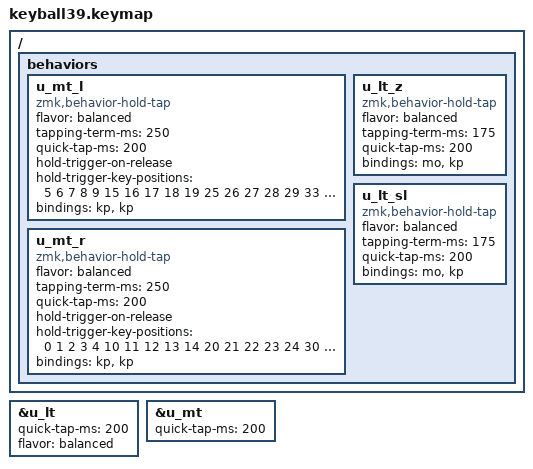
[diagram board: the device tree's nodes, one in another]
// Miryoku keymap for Keyball39
// https://github.com/manna-harbour/miryoku_zmk

#include "keyball39_custom_config.h"
#include "mapping/39/keyball39.h"
#include "../miryoku/miryoku/miryoku.dtsi"

// Charybdis-style hold-tap tuning (see keyball39_custom_config.h for the base
// override that wires these in).
//
// Keyball39 hand split (matrix-transform positions):
//   left  = 0-4 10-14 20-24 30-35   right = 5-9 15-19 25-29 36-38
/ {
    behaviors {
        // Home-row mods: Permissive Hold (balanced) + Chordal Hold (positional).
        // A mod holds when the OTHER hand OR a same-hand thumb (33-38) follows,
        // so alpha rolls (as/en) stay taps but mod+thumb chords (Ctrl+Space,
        // Ctrl+Bspc) fire. hold-trigger-on-release lets same-hand mod combos
        // still work. tapping-term 250.
        u_mt_l: u_mt_l {
            compatible = "zmk,behavior-hold-tap";
            #binding-cells = <2>;
            flavor = "balanced";
            tapping-term-ms = <250>;
            quick-tap-ms = <200>;
            hold-trigger-on-release;
            hold-trigger-key-positions = <5 6 7 8 9 15 16 17 18 19 25 26 27 28 29 33 34 35 36 37 38>;
            bindings = <&kp>, <&kp>;
        };
        u_mt_r: u_mt_r {
            compatible = "zmk,behavior-hold-tap";
            #binding-cells = <2>;
            flavor = "balanced";
            tapping-term-ms = <250>;
            quick-tap-ms = <200>;
            hold-trigger-on-release;
            hold-trigger-key-positions = <0 1 2 3 4 10 11 12 13 14 20 21 22 23 24 30 31 32 33 34 35 36 37 38>;
            bindings = <&kp>, <&kp>;
        };
        // Pointer key Z: balanced @175ms, unrestricted -- matches the / pointer
        // key (u_lt_sl) so a fast or long Z tap stays a tap instead of dropping
        // into the mouse layer. Still holds cleanly for same-hand chords.
        u_lt_z: u_lt_z {
            compatible = "zmk,behavior-hold-tap";
            #binding-cells = <2>;
            flavor = "balanced";
            tapping-term-ms = <175>;
            quick-tap-ms = <200>;
            bindings = <&mo>, <&kp>;
        };
        // Pointer key /: balanced @175ms, unrestricted (no positional list) so
        // it can still hold in same-hand chords, but won't misfire on slashes.
        u_lt_sl: u_lt_sl {
            compatible = "zmk,behavior-hold-tap";
            #binding-cells = <2>;
            flavor = "balanced";
            tapping-term-ms = <175>;
            quick-tap-ms = <200>;
            bindings = <&mo>, <&kp>;
        };
    };
};

// Enable tap-then-hold key repeat on ALL hold-taps. Re-pressing within 200ms of
// a tap fires the tap key and holds it -> continuous repeat (e.g. double-tap-
// hold Space/Bspc, or a home-row letter). The custom behaviors above set
// quick-tap-ms inline; these two patch Miryoku's own hold-taps: &u_lt (thumb
// layer-taps: Space/NAV, Bspc/NUM, Tab/FUN, Ret/SYM, Esc/MEDIA) and &u_mt
// (X/. RALT alt keys). NOTE: Miryoku uses &u_lt/&u_mt, NOT ZMK's built-in
// &lt/&mt -- overriding the built-ins here has no effect on this keymap.
&u_lt {
    quick-tap-ms = <200>;
    // Miryoku ships thumb layer-taps as "tap-preferred" (holds only if you
    // physically outlast the 200ms term). Fast rolls into a layer key -- e.g.
    // hold-Bspc(NUM)+minus for a hyphen -- then resolved as a Bspc tap. Balanced
    // holds the moment the interrupting key is released (the roll pattern),
    // while a solo thumb press under the term still taps cleanly.
    flavor = "balanced";
};
&u_mt {
    quick-tap-ms = <200>;
};
